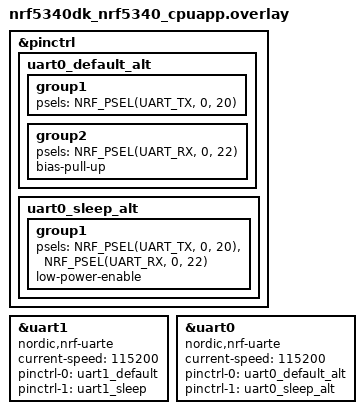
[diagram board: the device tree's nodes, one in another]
/* SPDX-License-Identifier: Apache-2.0 */

&pinctrl {
	uart0_default_alt: uart0_default_alt {
		group1 {
			psels = <NRF_PSEL(UART_TX, 0, 20)>;
		};
		group2 {
			psels = <NRF_PSEL(UART_RX, 0, 22)>;
			bias-pull-up;
		};
	};

	uart0_sleep_alt: uart0_sleep_alt {
		group1 {
			psels = <NRF_PSEL(UART_TX, 0, 20)>,
				<NRF_PSEL(UART_RX, 0, 22)>;
			low-power-enable;
		};
	};
};

&uart1 {
	compatible = "nordic,nrf-uarte";
	current-speed = <115200>;
	status = "okay";
	pinctrl-0 = <&uart1_default>;
	pinctrl-1 = <&uart1_sleep>;
	pinctrl-names = "default", "sleep";
};

&uart0 {
	compatible = "nordic,nrf-uarte";
	current-speed = <115200>;
	status = "okay";
	pinctrl-0 = <&uart0_default_alt>;
	pinctrl-1 = <&uart0_sleep_alt>;
	pinctrl-names = "default", "sleep";
};
